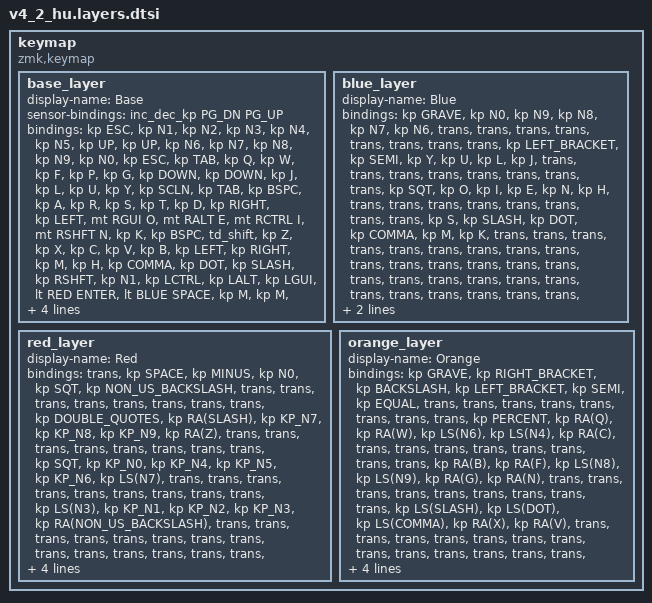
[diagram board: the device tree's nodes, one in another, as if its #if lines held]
/*
 * The layer tables of the HU MonoTypist, generated by tools/gen-keymap.mjs from layout/hu.json.
 * Do not edit this file: change layout/hu.json and run "node tools/gen-keymap.mjs".
 */

keymap {
    compatible = "zmk,keymap";

    base_layer {
        display-name = "Base";
        sensor-bindings = <&inc_dec_kp PG_DN PG_UP>;
        bindings = <
#if SIMPLE_MODE == 1
            &kp ESC        &kp N1         &kp N2         &kp N3         &kp N4         &kp N5         &kp UP         &kp UP         &kp N6         &kp N7         &kp N8         &kp N9         &kp N0         &kp ESC
#else
            &kp ESC        &kp C_AL_CALC  &kp LG(DOT)    &kp LS(LG(S))  &mac_git       &kp LG(V)      &kp UP         &kp UP         &kp N6         &kp N7         &kp N8         &kp N9         &kp N0         &kp ESC
#endif
            &kp TAB        &kp Q          &kp W          &kp F          &kp P          &kp G          &kp DOWN       &kp DOWN       &kp J          &kp L          &kp U          &kp Y          &kp SCLN       &kp TAB
            &kp BSPC       &kp A          &kp R          &kp S          &kp T          &kp D          &kp RIGHT      &kp LEFT       &mt RGUI O     &mt RALT E     &mt RCTRL I    &mt RSHFT N    &kp K          &kp BSPC
            &td_shift      &kp Z          &kp X          &kp C          &kp V          &kp B          &kp LEFT       &kp RIGHT      &kp M          &kp H          &kp COMMA      &kp DOT        &kp SLASH      &kp RSHFT
            &kp N1         &kp LCTRL      &kp LALT       &kp LGUI       &lt RED ENTER  &lt BLUE SPACE &kp M          &kp M          &kp N9         &kp N8         &kp RGUI       &kp BSPC       &lt NAV SPACE  &kp N0
            &kp N4         &kp N5         &kp N6         &kp N7         &kp N8         &lt ORANGE DEL &kp N9         &kp N1         &kp N5         &kp N4         &kp N3         &kp N2         &kp LSHFT      &kp N6
        >;
    };

    blue_layer {
        display-name = "Blue";
        bindings = <
            &kp GRAVE        &kp N0           &kp N9           &kp N8           &kp N7           &kp N6           &trans           &trans           &trans           &trans           &trans           &trans           &trans           &trans
            &kp LEFT_BRACKET &kp SEMI         &kp Y            &kp U            &kp L            &kp J            &trans           &trans           &trans           &trans           &trans           &trans           &trans           &trans
            &kp SQT          &kp O            &kp I            &kp E            &kp N            &kp H            &trans           &trans           &trans           &trans           &trans           &trans           &trans           &trans
            &kp S            &kp SLASH        &kp DOT          &kp COMMA        &kp M            &kp K            &trans           &trans           &trans           &trans           &trans           &trans           &trans           &trans
            &trans           &trans           &trans           &trans           &trans           &trans           &trans           &trans           &trans           &trans           &trans           &trans           &trans           &trans
            &trans           &trans           &trans           &trans           &trans           &trans           &trans           &trans           &trans           &trans           &trans           &trans           &trans           &trans
        >;
    };

    red_layer {
        display-name = "Red";
        bindings = <
            &trans                   &kp SPACE                &kp MINUS                &kp N0                   &kp SQT                  &kp NON_US_BACKSLASH     &trans                   &trans                   &trans                   &trans                   &trans                   &trans                   &trans                   &trans
            &kp DOUBLE_QUOTES        &kp RA(SLASH)            &kp KP_N7                &kp KP_N8                &kp KP_N9                &kp RA(Z)                &trans                   &trans                   &trans                   &trans                   &trans                   &trans                   &trans                   &trans
            &kp SQT                  &kp KP_N0                &kp KP_N4                &kp KP_N5                &kp KP_N6                &kp LS(N7)               &trans                   &trans                   &trans                   &trans                   &trans                   &trans                   &trans                   &trans
            &trans                   &kp LS(N3)               &kp KP_N1                &kp KP_N2                &kp KP_N3                &kp RA(NON_US_BACKSLASH) &trans                   &trans                   &trans                   &trans                   &trans                   &trans                   &trans                   &trans
            &trans                   &trans                   &trans                   &trans                   &trans                   &trans                   &trans                   &trans                   &trans                   &trans                   &trans                   &trans                   &trans                   &trans
            &trans                   &trans                   &trans                   &trans                   &trans                   &trans                   &trans                   &trans                   &trans                   &trans                   &trans                   &trans                   &trans                   &trans
        >;
    };

    orange_layer {
        display-name = "Orange";
        bindings = <
            &kp GRAVE         &kp RIGHT_BRACKET &kp BACKSLASH     &kp LEFT_BRACKET  &kp SEMI          &kp EQUAL         &trans            &trans            &trans            &trans            &trans            &trans            &trans            &trans
            &kp PERCENT       &kp RA(Q)         &kp RA(W)         &kp LS(N6)        &kp LS(N4)        &kp RA(C)         &trans            &trans            &trans            &trans            &trans            &trans            &trans            &trans
            &kp RA(B)         &kp RA(F)         &kp LS(N8)        &kp LS(N9)        &kp RA(G)         &kp RA(N)         &trans            &trans            &trans            &trans            &trans            &trans            &trans            &trans
            &trans            &kp LS(SLASH)     &kp LS(DOT)       &kp LS(COMMA)     &kp RA(X)         &kp RA(V)         &trans            &trans            &trans            &trans            &trans            &trans            &trans            &trans
            &trans            &trans            &trans            &trans            &trans            &trans            &trans            &trans            &trans            &trans            &trans            &trans            &trans            &trans
            &trans            &trans            &trans            &trans            &trans            &trans            &trans            &trans            &trans            &trans            &trans            &trans            &trans            &trans
        >;
    };
};
